# bcm2835_lpa register map
Vendor: BROADCOM; Series: BCM2835; File version: A
BCM2835 found in the Raspberry Pi 1 and Zero
CPU: CA72 r0p0, little endian, MPU, FPU, 2 interrupt priority bits
Registers are 32-bit, read-write, reset 0x0 unless marked. A register's access mark holds for its fields unless they carry their own. Offsets are from the block's base; lines under a group give offsets from that group; [hi:lo] are bit positions; {n}, {i} and the like mark numbered series; 'fields as' and 'values as' point back to an identical list; <NAME> marks a mode.

## Memory map
0x20003000 SYSTMR size 0x80 — Broadcom System Timer
0x20007000 DMA size 0xFF4
0x2000B000 LIC size 0x400 — Broadcom Legacy Interrupt Controller
0x2000B880 VCMAILBOX size 0x40 — Mailboxes for talking to/from VideoCore
0x20100000 PM size 0x40 — Broadcom Power Manager
0x20101098 CM_PCM size 0x8 — Broadcom Clock Manager
0x201010A0 CM_PWM size 0x8
0x20200000 GPIO size 0xF4 — Pin level and mux control
0x20201000 UART0 blocks up to offset 0x4C — ARM Prime Cell PL011
0x20203000 PCM size 0x24
0x20204000 SPI0 size 0x200 — Broadcom SPI Controller
0x20205000 BSC0 size 0x200 — Broadcom Serial Controller (I2C compatible)
0x2020C000 PWM0 size 0x80 — Broadcom PWM
0x20215000 AUX size 0x40 — Three auxiliary peripherals
0x20215040 UART1 size 0x40 — Mini UART
0x20215080 SPI1 size 0x40 — Aux SPI
0x202150C0 SPI2 size 0x40 — Aux SPI
0x20300000 EMMC size 0x100 — Arasan SD3.0 Host AHB eMMC 4.4
0x20804000 BSC1 size 0x200
0x20805000 BSC2 size 0x200
0x20980000 USB_OTG_GLOBAL size 0x131 — USB on the go high speed
0x20980400 USB_OTG_HOST size 0x400 — USB on the go high speed
0x20980800 USB_OTG_DEVICE size 0x400 — USB on the go high speed
0x20980E00 USB_OTG_PWRCLK size 0x400 — USB on the go high speed power control

## Interrupts
0 TIMER_0 (SYSTMR) — Timer 0 matched
1 TIMER_1 (SYSTMR) — Timer 1 matched
2 TIMER_2 (SYSTMR) — Timer 2 matched
3 TIMER_3 (SYSTMR) — Timer 3 matched
9 USB (USB_OTG_GLOBAL) — USB interrupt
29 AUX — Interrupt from AUX
49 GPIO0 (GPIO) — Interrupt from bank 0
50 GPIO1 (GPIO) — Interrupt from bank 1
51 GPIO2 (GPIO) — Interrupt from bank 2
52 GPIO — OR of all GPIO interrupts
53 I2C (BSC0) — OR of all I2C interrupts
54 SPI (SPI0) — OR of all SPI interrupts except 1 and 2
57 UART (UART0) — OR of all UART interrupts except 1
62 EMMC — OR of EMMC and EMMC2

## VCMAILBOX — Mailboxes for talking to/from VideoCore
Base 0x2000B880
0x00 READ ro — Read messages from the VideoCore
0x10 PEEK0
0x14 SENDER0
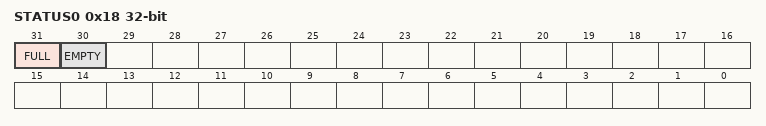
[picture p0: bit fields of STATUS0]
0x18 STATUS0
  [31] FULL ro, [30] EMPTY ro
0x1C CONFIG0
  [0] IRQEN — Enable the interrupt when data is available
0x20 WRITE wo — Write messages to the VideoCore
0x30 PEEK1
0x34 SENDER1
0x38 STATUS1
0x3C CONFIG1

## PM — Broadcom Power Manager
Base 0x20100000
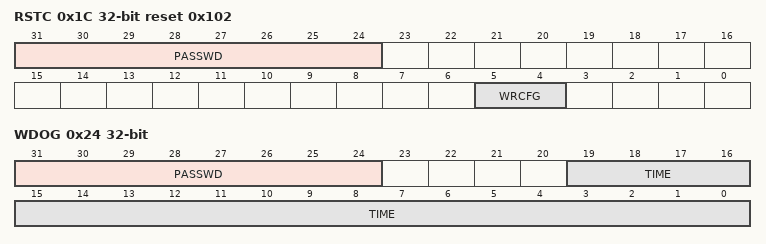
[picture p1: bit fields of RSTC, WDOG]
0x1C RSTC reset 0x102 — Reset Control
  [31:24] PASSWD wo — Password. Always 0x5a
    90=PASSWD
  [5:4] WRCFG — Watchdog reset config
    2=FULL_RESET
0x24 WDOG — Watchdog control
  [31:24] PASSWD wo — Password. Always 0x5a
    90=PASSWD
  [19:0] TIME — Time until watchdog alarm

## CM_PCM — Broadcom Clock Manager
Base 0x20101098
Same registers: CM_PWM 0x201010A0
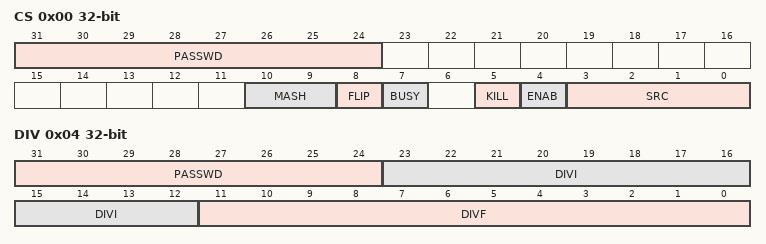
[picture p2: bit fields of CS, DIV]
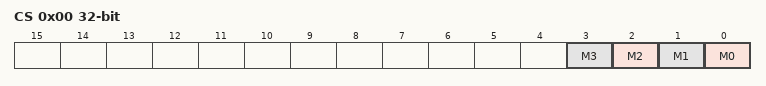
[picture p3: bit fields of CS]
0x00 CS — Control / Status
  [31:24] PASSWD wo — Password. Always 0x5a
    90=PASSWD
  [10:9] MASH — MASH control, stage count
  [8] FLIP — Generate an edge on output. (For testing)
  [7] BUSY ro — Indicates the clock generator is running
  [5] KILL — Stop and reset the generator
  [4] ENAB — Enable the clock generator. (Switch SRC first.)
  [3:0] SRC — Clock source
    other=GND; 1=XOSC; 2=TEST0; 3=TEST1; 4=PLLA; 5=PLLB; 6=PLLC; 7=HDMI
0x04 DIV — Clock divisor
  [31:24] PASSWD wo — Password. Always 0x5a
    90=PASSWD
  [23:12] DIVI — Integer part of divisor
  [11:0] DIVF — Fractional part of divisor

## SYSTMR — Broadcom System Timer
Base 0x20003000
0x00 CS — Control / Status
  [n] M{n} write-1-clears (n=0..3) — System timer match {n}
0x04 CLO ro — Lower 32 bits for the free running counter
0x08 CHI ro — Higher 32 bits for the free running counter
{0xC+4i} C{i} (i=0..3) — Compare channel {i}
